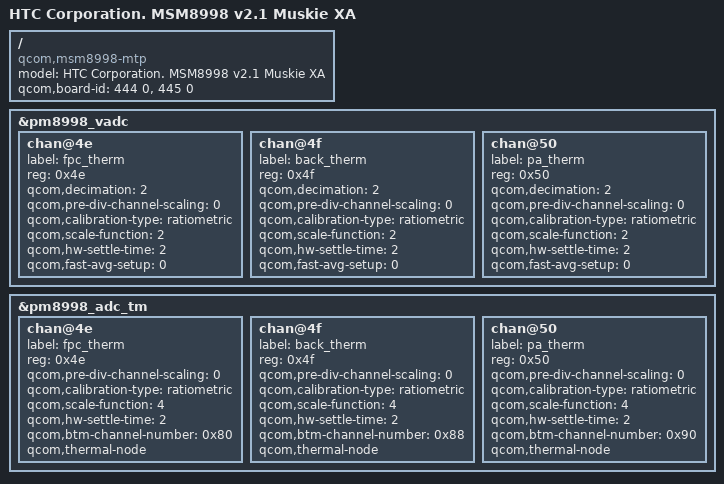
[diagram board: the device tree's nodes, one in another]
/* Copyright (c) 2016, The Linux Foundation. All rights reserved.
 *
 * This program is free software; you can redistribute it and/or modify
 * it under the terms of the GNU General Public License version 2 and
 * only version 2 as published by the Free Software Foundation.
 *
 * This program is distributed in the hope that it will be useful,
 * but WITHOUT ANY WARRANTY; without even the implied warranty of
 * MERCHANTABILITY or FITNESS FOR A PARTICULAR PURPOSE.  See the
 * GNU General Public License for more details.
 */


/dts-v1/;

#include "../qcom/msm8998-v2.1.dtsi"
#include "../qcom/msm8998-mtp.dtsi"
#include "msm8998-htc_muskie.dtsi"
#include "msm8998-htc-nfc.dtsi"
#include "msm8998-htc-easel.dtsi"
#include "msm8998-camera-sensor-muskie-xa.dtsi"
#include "msm8998-htc-fingerprint-muskie-xa.dtsi"
#include "msm8998-htc-usb-xa.dtsi"
#include "msm8998-htc-haptics-xa.dtsi"
#include "msm8998-htc-led-xa.dtsi"

/ {
	model = "HTC Corporation. MSM8998 v2.1 Muskie XA";
	compatible = "qcom,msm8998-mtp", "qcom,msm8998", "qcom,mtp";
	qcom,board-id = <444 0>, <445 0>;
};

&pm8998_vadc {
	chan@4e {
		label = "fpc_therm";
		reg = <0x4e>;
		qcom,decimation = <2>;
		qcom,pre-div-channel-scaling = <0>;
		qcom,calibration-type = "ratiometric";
		qcom,scale-function = <2>;
		qcom,hw-settle-time = <2>;
		qcom,fast-avg-setup = <0>;
	};

	chan@4f {
		label = "back_therm";
		reg = <0x4f>;
		qcom,decimation = <2>;
		qcom,pre-div-channel-scaling = <0>;
		qcom,calibration-type = "ratiometric";
		qcom,scale-function = <2>;
		qcom,hw-settle-time = <2>;
		qcom,fast-avg-setup = <0>;
	};

	chan@50 {
		label = "pa_therm";
		reg = <0x50>;
		qcom,decimation = <2>;
		qcom,pre-div-channel-scaling = <0>;
		qcom,calibration-type = "ratiometric";
		qcom,scale-function = <2>;
		qcom,hw-settle-time = <2>;
		qcom,fast-avg-setup = <0>;
	};
};

&pm8998_adc_tm {
	chan@4e {
		label = "fpc_therm";
		reg = <0x4e>;
		qcom,pre-div-channel-scaling = <0>;
		qcom,calibration-type = "ratiometric";
		qcom,scale-function = <4>;
		qcom,hw-settle-time = <2>;
		qcom,btm-channel-number = <0x80>;
		qcom,thermal-node;
	};

	chan@4f {
		label = "back_therm";
		reg = <0x4f>;
		qcom,pre-div-channel-scaling = <0>;
		qcom,calibration-type = "ratiometric";
		qcom,scale-function = <4>;
		qcom,hw-settle-time = <2>;
		qcom,btm-channel-number = <0x88>;
		qcom,thermal-node;
	};

	chan@50 {
		label = "pa_therm";
		reg = <0x50>;
		qcom,pre-div-channel-scaling = <0>;
		qcom,calibration-type = "ratiometric";
		qcom,scale-function = <4>;
		qcom,hw-settle-time = <2>;
		qcom,btm-channel-number = <0x90>;
		qcom,thermal-node;
	};
};
